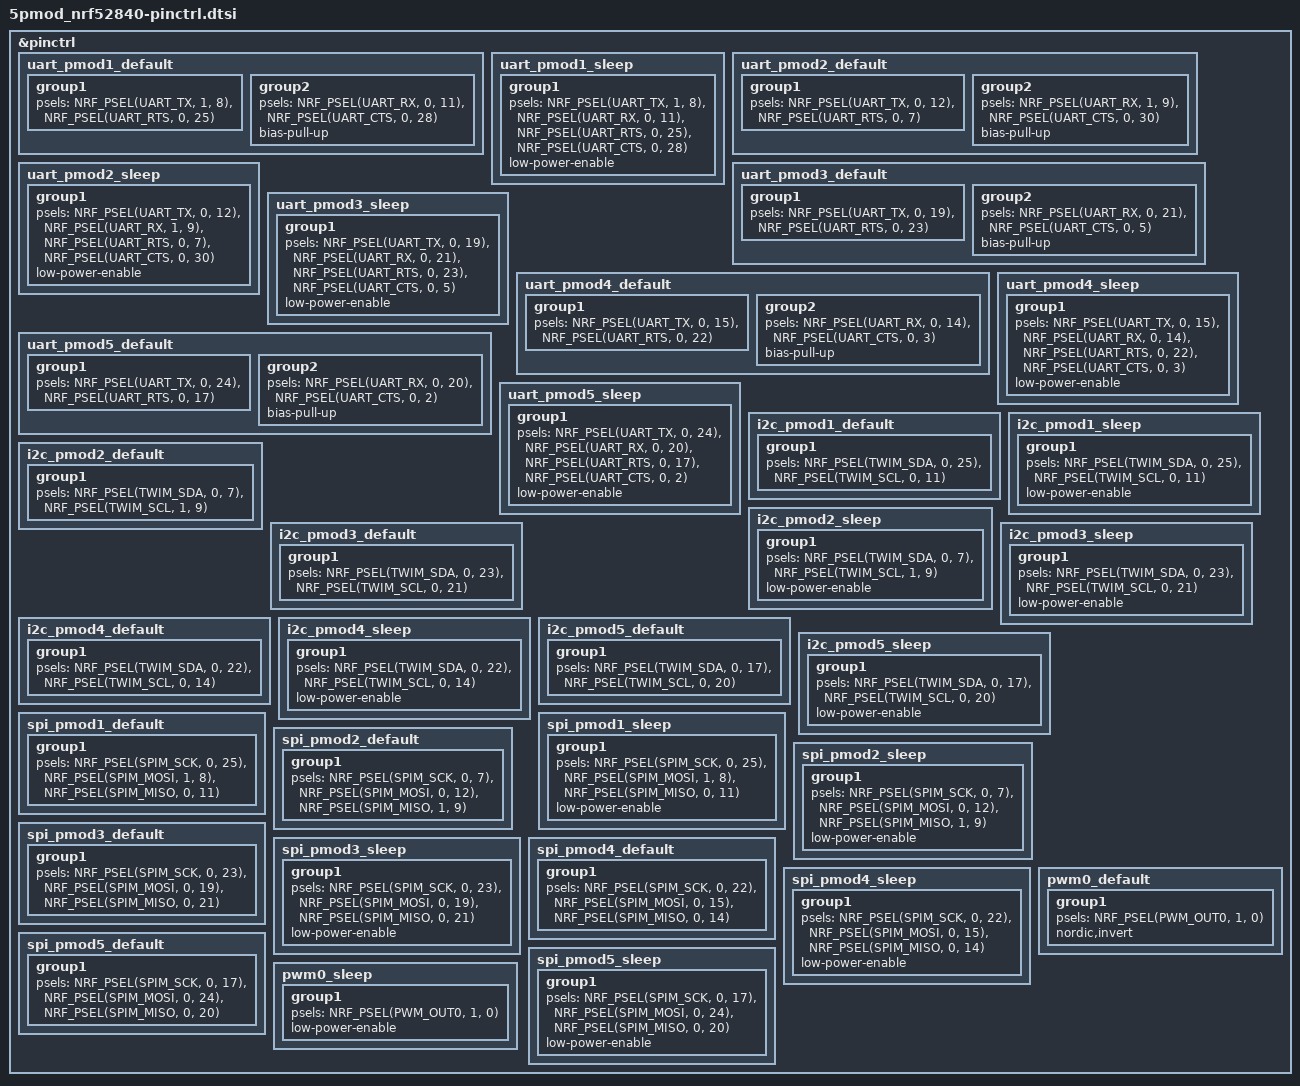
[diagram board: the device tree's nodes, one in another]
/*
 * SPDX-License-Identifier: Apache-2.0
 */

&pinctrl {
	uart_pmod1_default: uart_pmod1_default {
		group1 {
			psels = <NRF_PSEL(UART_TX, 1, 8)>,
				<NRF_PSEL(UART_RTS, 0, 25)>;
		};
		group2 {
			psels = <NRF_PSEL(UART_RX, 0, 11)>,
				<NRF_PSEL(UART_CTS, 0, 28)>;
			bias-pull-up;
		};
	};

	uart_pmod1_sleep: uart_pmod1_sleep {
		group1 {
			psels = <NRF_PSEL(UART_TX, 1, 8)>,
				<NRF_PSEL(UART_RX, 0, 11)>,
				<NRF_PSEL(UART_RTS, 0, 25)>,
				<NRF_PSEL(UART_CTS, 0, 28)>;
			low-power-enable;
		};
	};

	uart_pmod2_default: uart_pmod2_default {
		group1 {
			psels = <NRF_PSEL(UART_TX, 0, 12)>,
				<NRF_PSEL(UART_RTS, 0, 7)>;
		};
		group2 {
			psels = <NRF_PSEL(UART_RX, 1, 9)>,
				<NRF_PSEL(UART_CTS, 0, 30)>;
			bias-pull-up;
		};
	};

	uart_pmod2_sleep: uart_pmod2_sleep {
		group1 {
			psels = <NRF_PSEL(UART_TX, 0, 12)>,
				<NRF_PSEL(UART_RX, 1, 9)>,
				<NRF_PSEL(UART_RTS, 0, 7)>,
				<NRF_PSEL(UART_CTS, 0, 30)>;
			low-power-enable;
		};
	};

	uart_pmod3_default: uart_pmod3_default {
		group1 {
			psels = <NRF_PSEL(UART_TX, 0, 19)>,
				<NRF_PSEL(UART_RTS, 0, 23)>;
		};
		group2 {
			psels = <NRF_PSEL(UART_RX, 0, 21)>,
				<NRF_PSEL(UART_CTS, 0, 5)>;
			bias-pull-up;
		};
	};

	uart_pmod3_sleep: uart_pmod3_sleep {
		group1 {
			psels = <NRF_PSEL(UART_TX, 0, 19)>,
				<NRF_PSEL(UART_RX, 0, 21)>,
				<NRF_PSEL(UART_RTS, 0, 23)>,
				<NRF_PSEL(UART_CTS, 0, 5)>;
			low-power-enable;
		};
	};

	uart_pmod4_default: uart_pmod4_default {
		group1 {
			psels = <NRF_PSEL(UART_TX, 0, 15)>,
				<NRF_PSEL(UART_RTS, 0, 22)>;
		};
		group2 {
			psels = <NRF_PSEL(UART_RX, 0, 14)>,
				<NRF_PSEL(UART_CTS, 0, 3)>;
			bias-pull-up;
		};
	};

	uart_pmod4_sleep: uart_pmod4_sleep {
		group1 {
			psels = <NRF_PSEL(UART_TX, 0, 15)>,
				<NRF_PSEL(UART_RX, 0, 14)>,
				<NRF_PSEL(UART_RTS, 0, 22)>,
				<NRF_PSEL(UART_CTS, 0, 3)>;
			low-power-enable;
		};
	};


	uart_pmod5_default: uart_pmod5_default {
		group1 {
			psels = <NRF_PSEL(UART_TX, 0, 24)>,
				<NRF_PSEL(UART_RTS, 0, 17)>;
		};
		group2 {
			psels = <NRF_PSEL(UART_RX, 0, 20)>,
				<NRF_PSEL(UART_CTS, 0, 2)>;
			bias-pull-up;
		};
	};

	uart_pmod5_sleep: uart_pmod5_sleep {
		group1 {
			psels = <NRF_PSEL(UART_TX, 0, 24)>,
				<NRF_PSEL(UART_RX, 0, 20)>,
				<NRF_PSEL(UART_RTS, 0, 17)>,
				<NRF_PSEL(UART_CTS, 0, 2)>;
			low-power-enable;
		};
	};

	i2c_pmod1_default: i2c_pmod1_default {
		group1 {
			psels = <NRF_PSEL(TWIM_SDA, 0, 25)>,
				<NRF_PSEL(TWIM_SCL, 0, 11)>;
		};
	};

	i2c_pmod1_sleep: i2c_pmod1_sleep {
		group1 {
			psels = <NRF_PSEL(TWIM_SDA, 0, 25)>,
				<NRF_PSEL(TWIM_SCL, 0, 11)>;
			low-power-enable;
		};
	};

	i2c_pmod2_default: i2c_pmod2_default {
		group1 {
			psels = <NRF_PSEL(TWIM_SDA, 0, 7)>,
				<NRF_PSEL(TWIM_SCL, 1, 9)>;
		};
	};

	i2c_pmod2_sleep: i2c_pmod2_sleep {
		group1 {
			psels = <NRF_PSEL(TWIM_SDA, 0, 7)>,
				<NRF_PSEL(TWIM_SCL, 1, 9)>;
			low-power-enable;
		};
	};

	i2c_pmod3_default: i2c_pmod3_default {
		group1 {
			psels = <NRF_PSEL(TWIM_SDA, 0, 23)>,
				<NRF_PSEL(TWIM_SCL, 0, 21)>;
		};
	};

	i2c_pmod3_sleep: i2c_pmod3_sleep {
		group1 {
			psels = <NRF_PSEL(TWIM_SDA, 0, 23)>,
				<NRF_PSEL(TWIM_SCL, 0, 21)>;
			low-power-enable;
		};
	};

	i2c_pmod4_default: i2c_pmod4_default {
		group1 {
			psels = <NRF_PSEL(TWIM_SDA, 0, 22)>,
				<NRF_PSEL(TWIM_SCL, 0, 14)>;
		};
	};

	i2c_pmod4_sleep: i2c_pmod4_sleep {
		group1 {
			psels = <NRF_PSEL(TWIM_SDA, 0, 22)>,
				<NRF_PSEL(TWIM_SCL, 0, 14)>;
			low-power-enable;
		};
	};

	i2c_pmod5_default: i2c_pmod5_default {
		group1 {
			psels = <NRF_PSEL(TWIM_SDA, 0, 17)>,
				<NRF_PSEL(TWIM_SCL, 0, 20)>;
		};
	};

	i2c_pmod5_sleep: i2c_pmod5_sleep {
		group1 {
			psels = <NRF_PSEL(TWIM_SDA, 0, 17)>,
				<NRF_PSEL(TWIM_SCL, 0, 20)>;
			low-power-enable;
		};
	};

	spi_pmod1_default: spi_pmod1_default {
		group1 {
			psels = <NRF_PSEL(SPIM_SCK, 0, 25)>,
				<NRF_PSEL(SPIM_MOSI, 1, 8)>,
				<NRF_PSEL(SPIM_MISO, 0, 11)>;
		};
	};

	spi_pmod1_sleep: spi_pmod1_sleep {
		group1 {
			psels = <NRF_PSEL(SPIM_SCK, 0, 25)>,
				<NRF_PSEL(SPIM_MOSI, 1, 8)>,
				<NRF_PSEL(SPIM_MISO, 0, 11)>;
			low-power-enable;
		};
	};

	spi_pmod2_default: spi_pmod2_default {
		group1 {
			psels = <NRF_PSEL(SPIM_SCK, 0, 7)>,
				<NRF_PSEL(SPIM_MOSI, 0, 12)>,
				<NRF_PSEL(SPIM_MISO, 1, 9)>;
		};
	};

	spi_pmod2_sleep: spi_pmod2_sleep {
		group1 {
			psels = <NRF_PSEL(SPIM_SCK, 0, 7)>,
				<NRF_PSEL(SPIM_MOSI, 0, 12)>,
				<NRF_PSEL(SPIM_MISO, 1, 9)>;
			low-power-enable;
		};
	};

	spi_pmod3_default: spi_pmod3_default {
		group1 {
			psels = <NRF_PSEL(SPIM_SCK, 0, 23)>,
				<NRF_PSEL(SPIM_MOSI, 0, 19)>,
				<NRF_PSEL(SPIM_MISO, 0, 21)>;
		};
	};

	spi_pmod3_sleep: spi_pmod3_sleep {
		group1 {
			psels = <NRF_PSEL(SPIM_SCK, 0, 23)>,
				<NRF_PSEL(SPIM_MOSI, 0, 19)>,
				<NRF_PSEL(SPIM_MISO, 0, 21)>;
			low-power-enable;
		};
	};

	spi_pmod4_default: spi_pmod4_default {
		group1 {
			psels = <NRF_PSEL(SPIM_SCK, 0, 22)>,
				<NRF_PSEL(SPIM_MOSI, 0, 15)>,
				<NRF_PSEL(SPIM_MISO, 0, 14)>;
		};
	};

	spi_pmod4_sleep: spi_pmod4_sleep {
		group1 {
			psels = <NRF_PSEL(SPIM_SCK, 0, 22)>,
				<NRF_PSEL(SPIM_MOSI, 0, 15)>,
				<NRF_PSEL(SPIM_MISO, 0, 14)>;
			low-power-enable;
		};
	};

	spi_pmod5_default: spi_pmod5_default {
		group1 {
			psels = <NRF_PSEL(SPIM_SCK, 0, 17)>,
				<NRF_PSEL(SPIM_MOSI, 0, 24)>,
				<NRF_PSEL(SPIM_MISO, 0, 20)>;
		};
	};

	spi_pmod5_sleep: spi_pmod5_sleep {
		group1 {
			psels = <NRF_PSEL(SPIM_SCK, 0, 17)>,
				<NRF_PSEL(SPIM_MOSI, 0, 24)>,
				<NRF_PSEL(SPIM_MISO, 0, 20)>;
			low-power-enable;
		};
	};

	pwm0_default: pwm0_default {
		group1 {
			psels = <NRF_PSEL(PWM_OUT0, 1, 0)>;
			nordic,invert;
		};
	};

	pwm0_sleep: pwm0_sleep {
		group1 {
			psels = <NRF_PSEL(PWM_OUT0, 1, 0)>;
			low-power-enable;
		};
	};
};
